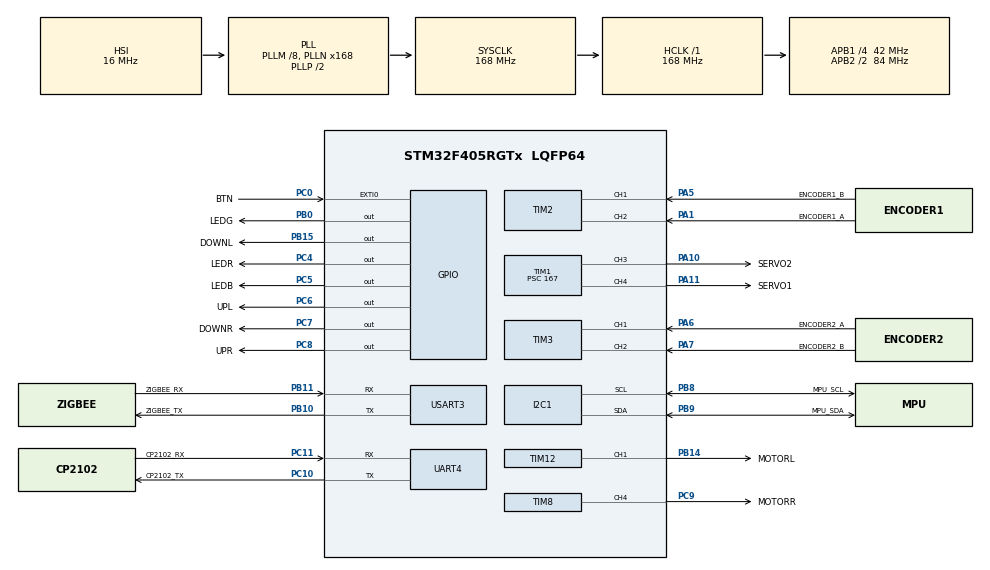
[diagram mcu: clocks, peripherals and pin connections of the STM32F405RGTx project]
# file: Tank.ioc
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Dma.Request0=UART4_RX
Dma.Request1=USART3_RX
Dma.UART4_RX.0.Direction=DMA_PERIPH_TO_MEMORY
Dma.UART4_RX.0.FIFOMode=DMA_FIFOMODE_DISABLE
Dma.UART4_RX.0.Instance=DMA1_Stream2
Dma.UART4_RX.0.MemDataAlignment=DMA_MDATAALIGN_BYTE
Dma.UART4_RX.0.MemInc=DMA_MINC_ENABLE
Dma.UART4_RX.0.Mode=DMA_NORMAL
Dma.UART4_RX.0.PeriphDataAlignment=DMA_PDATAALIGN_BYTE
Dma.UART4_RX.0.PeriphInc=DMA_PINC_DISABLE
Dma.UART4_RX.0.Priority=DMA_PRIORITY_LOW
Dma.USART3_RX.1.Direction=DMA_PERIPH_TO_MEMORY
Dma.USART3_RX.1.FIFOMode=DMA_FIFOMODE_DISABLE
Dma.USART3_RX.1.Instance=DMA1_Stream1
Dma.USART3_RX.1.MemDataAlignment=DMA_MDATAALIGN_BYTE
Dma.USART3_RX.1.MemInc=DMA_MINC_ENABLE
Dma.USART3_RX.1.Mode=DMA_NORMAL
Dma.USART3_RX.1.PeriphDataAlignment=DMA_PDATAALIGN_BYTE
Dma.USART3_RX.1.PeriphInc=DMA_PINC_DISABLE
Dma.USART3_RX.1.Priority=DMA_PRIORITY_LOW
Mcu.Family=STM32F4
Mcu.Name=STM32F405RGTx
Mcu.Package=LQFP64
NVIC.DMA1_Stream1_IRQn=true\:0\:0\:false\:false\:true\:false\:true
NVIC.DMA1_Stream2_IRQn=true\:0\:0\:false\:false\:true\:false\:true
NVIC.PriorityGroup=NVIC_PRIORITYGROUP_4
NVIC.UART4_IRQn=true\:0\:0\:false\:false\:true\:true\:true
NVIC.USART3_IRQn=true\:0\:0\:false\:false\:true\:true\:true
PA1.GPIO_Label=ENCODER1_A
PA1.GPIO_PuPd=GPIO_PULLUP
PA1.Signal=S_TIM2_CH2
PA10.GPIO_Label=SERVO2
PA10.Signal=S_TIM1_CH3
PA11.GPIO_Label=SERVO1
PA11.Signal=S_TIM1_CH4
PA13.Mode=Serial_Wire
PA13.Signal=SYS_JTMS-SWDIO
PA14.Mode=Serial_Wire
PA14.Signal=SYS_JTCK-SWCLK
PA5.GPIO_Label=ENCODER1_B
PA5.GPIO_PuPd=GPIO_PULLUP
PA5.Signal=S_TIM2_CH1_ETR
PA6.GPIO_Label=ENCODER2_A
PA6.GPIO_PuPd=GPIO_PULLUP
PA6.Signal=S_TIM3_CH1
PA7.GPIO_Label=ENCODER2_B
PA7.GPIO_PuPd=GPIO_PULLUP
PA7.Signal=S_TIM3_CH2
PB0.GPIO_Label=LEDG
PB0.Signal=GPIO_Output
PB10.GPIO_Label=ZIGBEE_TX
PB10.Mode=Asynchronous
PB10.Signal=USART3_TX
PB11.GPIO_Label=ZIGBEE_RX
PB11.Mode=Asynchronous
PB11.Signal=USART3_RX
PB14.GPIO_Label=MOTORL
PB14.Signal=S_TIM12_CH1
PB15.GPIO_Label=DOWNL
PB15.Signal=GPIO_Output
PB8.GPIO_Label=MPU_SCL
PB8.Mode=I2C
PB8.Signal=I2C1_SCL
PB9.GPIO_Label=MPU_SDA
PB9.Mode=I2C
PB9.Signal=I2C1_SDA
PC0.GPIO_Label=BTN
PC0.Signal=GPXTI0
PC10.GPIO_Label=CP2102_TX
PC10.Mode=Asynchronous
PC10.Signal=UART4_TX
PC11.GPIO_Label=CP2102_RX
PC11.Mode=Asynchronous
PC11.Signal=UART4_RX
PC4.GPIO_Label=LEDR
PC4.Signal=GPIO_Output
PC5.GPIO_Label=LEDB
PC5.Signal=GPIO_Output
PC6.GPIO_Label=UPL
PC6.Signal=GPIO_Output
PC7.GPIO_Label=DOWNR
PC7.Signal=GPIO_Output
PC8.GPIO_Label=UPR
PC8.Signal=GPIO_Output
PC9.GPIO_Label=MOTORR
PC9.Signal=S_TIM8_CH4
PH0-OSC_IN.Mode=HSE-External-Clock-Source
PH0-OSC_IN.Signal=RCC_OSC_IN
PH1-OSC_OUT.Mode=HSE-External-Clock-Source
PH1-OSC_OUT.Signal=RCC_OSC_OUT
ProjectManager.HeapSize=0x200
ProjectManager.StackSize=0x400
ProjectManager.TargetToolchain=STM32CubeIDE
RCC.48MHZClocksFreq_Value=84000000
RCC.AHBFreq_Value=168000000
RCC.APB1CLKDivider=RCC_HCLK_DIV4
RCC.APB1Freq_Value=42000000
RCC.APB1TimFreq_Value=84000000
RCC.APB2CLKDivider=RCC_HCLK_DIV2
RCC.APB2Freq_Value=84000000
RCC.APB2TimFreq_Value=168000000
RCC.CortexFreq_Value=168000000
RCC.HCLKFreq_Value=168000000
RCC.HSE_VALUE=25000000
RCC.HSI_VALUE=16000000
RCC.LSE_VALUE=32768
RCC.PLLM=8
RCC.PLLN=168
RCC.SYSCLKFreq_VALUE=168000000
RCC.SYSCLKSource=RCC_SYSCLKSOURCE_PLLCLK
RCC.VCOOutputFreq_Value=336000000
SH.S_TIM12_CH1.0=TIM12_CH1,PWM Generation1 CH1
SH.S_TIM1_CH3.0=TIM1_CH3,PWM Generation3 CH3
SH.S_TIM1_CH4.0=TIM1_CH4,PWM Generation4 CH4
SH.S_TIM2_CH1_ETR.0=TIM2_CH1,Encoder_Interface
SH.S_TIM2_CH2.0=TIM2_CH2,Encoder_Interface
SH.S_TIM3_CH1.0=TIM3_CH1,Encoder_Interface
SH.S_TIM3_CH2.0=TIM3_CH2,Encoder_Interface
SH.S_TIM8_CH4.0=TIM8_CH4,PWM Generation4 CH4
TIM1.Channel-PWM\ Generation3\ CH3=TIM_CHANNEL_3
TIM1.Channel-PWM\ Generation4\ CH4=TIM_CHANNEL_4
TIM1.Period=19999
TIM1.Prescaler=167
TIM12.Channel-PWM\ Generation1\ CH1=TIM_CHANNEL_1
TIM12.Period=3359
TIM8.Channel-PWM\ Generation4\ CH4=TIM_CHANNEL_4
TIM8.Period=3359
UART4.VirtualMode=Asynchronous
USART3.VirtualMode=VM_ASYNC
board=custom

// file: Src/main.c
/* USER CODE BEGIN Header */
/**
  ******************************************************************************
  * @file           : main.c
  * @brief          : Main program body
  ******************************************************************************
  * @attention
  *
  * <h2><center>&copy; Copyright (c) 2020 STMicroelectronics.
  * All rights reserved.</center></h2>
  *
  * This software component is licensed by ST under BSD 3-Clause license,
  * the "License"; You may not use this file except in compliance with the
  * License. You may obtain a copy of the License at:
  *                        opensource.org/licenses/BSD-3-Clause
  *
  ******************************************************************************
  */
/* USER CODE END Header */

#include "main.h"

I2C_HandleTypeDef hi2c1;

TIM_HandleTypeDef htim1;
TIM_HandleTypeDef htim2;
TIM_HandleTypeDef htim3;
TIM_HandleTypeDef htim8;
TIM_HandleTypeDef htim12;

UART_HandleTypeDef huart4;
UART_HandleTypeDef huart3;
DMA_HandleTypeDef hdma_uart4_rx;
DMA_HandleTypeDef hdma_usart3_rx;

/* USER CODE BEGIN PV */

extern char UARTgetchar[1],UARTbuffer[20];
extern uint8_t newblockdata;

/* USER CODE END PV */

void SystemClock_Config(void);
static void MX_GPIO_Init(void);
static void MX_DMA_Init(void);
static void MX_I2C1_Init(void);
static void MX_TIM1_Init(void);
static void MX_TIM2_Init(void);
static void MX_TIM3_Init(void);
static void MX_TIM8_Init(void);
static void MX_UART4_Init(void);
static void MX_USART3_UART_Init(void);
static void MX_TIM12_Init(void);

/* USER CODE BEGIN 0 */
void HAL_UART_RxCpltCallback(UART_HandleTypeDef *huart)
{
	switch (huart->Instance) {
		case UART4:

			break;
		default:
			break;
	}
}
/* USER CODE END 0 */

int main(void)
{

  /* MCU Configuration--------------------------------------------------------*/

  /* Reset of all peripherals, Initializes the Flash interface and the Systick. */
  HAL_Init();

  /* USER CODE BEGIN Init */
  HAL_UART_Receive_IT(&huart4, UARTgetchar, 1);
  /* USER CODE END Init */

  /* Configure the system clock */
  SystemClock_Config();

  /* Initialize all configured peripherals */
  MX_GPIO_Init();
  MX_DMA_Init();
  MX_I2C1_Init();
  MX_TIM1_Init();
  MX_TIM2_Init();
  MX_TIM3_Init();
  MX_TIM8_Init();
  MX_UART4_Init();
  MX_USART3_UART_Init();
  MX_TIM12_Init();

  /* Infinite loop */
  while (1)
  {

  }
}

void SystemClock_Config(void)
{
  RCC_OscInitTypeDef RCC_OscInitStruct = {0};
  RCC_ClkInitTypeDef RCC_ClkInitStruct = {0};

  /** Configure the main internal regulator output voltage
  */
  __HAL_RCC_PWR_CLK_ENABLE();
  __HAL_PWR_VOLTAGESCALING_CONFIG(PWR_REGULATOR_VOLTAGE_SCALE1);
  /** Initializes the CPU, AHB and APB busses clocks
  */
  RCC_OscInitStruct.OscillatorType = RCC_OSCILLATORTYPE_HSI;
  RCC_OscInitStruct.HSIState = RCC_HSI_ON;
  RCC_OscInitStruct.HSICalibrationValue = RCC_HSICALIBRATION_DEFAULT;
  RCC_OscInitStruct.PLL.PLLState = RCC_PLL_ON;
  RCC_OscInitStruct.PLL.PLLSource = RCC_PLLSOURCE_HSI;
  RCC_OscInitStruct.PLL.PLLM = 8;
  RCC_OscInitStruct.PLL.PLLN = 168;
  RCC_OscInitStruct.PLL.PLLP = RCC_PLLP_DIV2;
  RCC_OscInitStruct.PLL.PLLQ = 4;
  if (HAL_RCC_OscConfig(&RCC_OscInitStruct) != HAL_OK)
  {
    Error_Handler();
  }
  /** Initializes the CPU, AHB and APB busses clocks
  */
  RCC_ClkInitStruct.ClockType = RCC_CLOCKTYPE_HCLK|RCC_CLOCKTYPE_SYSCLK
                              |RCC_CLOCKTYPE_PCLK1|RCC_CLOCKTYPE_PCLK2;
  RCC_ClkInitStruct.SYSCLKSource = RCC_SYSCLKSOURCE_PLLCLK;
  RCC_ClkInitStruct.AHBCLKDivider = RCC_SYSCLK_DIV1;
  RCC_ClkInitStruct.APB1CLKDivider = RCC_HCLK_DIV4;
  RCC_ClkInitStruct.APB2CLKDivider = RCC_HCLK_DIV2;

  if (HAL_RCC_ClockConfig(&RCC_ClkInitStruct, FLASH_LATENCY_5) != HAL_OK)
  {
    Error_Handler();
  }
}

static void MX_I2C1_Init(void)
{

  hi2c1.Instance = I2C1;
  hi2c1.Init.ClockSpeed = 100000;
  hi2c1.Init.DutyCycle = I2C_DUTYCYCLE_2;
  hi2c1.Init.OwnAddress1 = 0;
  hi2c1.Init.AddressingMode = I2C_ADDRESSINGMODE_7BIT;
  hi2c1.Init.DualAddressMode = I2C_DUALADDRESS_DISABLE;
  hi2c1.Init.OwnAddress2 = 0;
  hi2c1.Init.GeneralCallMode = I2C_GENERALCALL_DISABLE;
  hi2c1.Init.NoStretchMode = I2C_NOSTRETCH_DISABLE;
  if (HAL_I2C_Init(&hi2c1) != HAL_OK)
  {
    Error_Handler();
  }

}

static void MX_TIM1_Init(void)
{

  TIM_MasterConfigTypeDef sMasterConfig = {0};
  TIM_OC_InitTypeDef sConfigOC = {0};
  TIM_BreakDeadTimeConfigTypeDef sBreakDeadTimeConfig = {0};

  htim1.Instance = TIM1;
  htim1.Init.Prescaler = 167;
  htim1.Init.CounterMode = TIM_COUNTERMODE_UP;
  htim1.Init.Period = 19999;
  htim1.Init.ClockDivision = TIM_CLOCKDIVISION_DIV1;
  htim1.Init.RepetitionCounter = 0;
  htim1.Init.AutoReloadPreload = TIM_AUTORELOAD_PRELOAD_DISABLE;
  if (HAL_TIM_PWM_Init(&htim1) != HAL_OK)
  {
    Error_Handler();
  }
  sMasterConfig.MasterOutputTrigger = TIM_TRGO_RESET;
  sMasterConfig.MasterSlaveMode = TIM_MASTERSLAVEMODE_DISABLE;
  if (HAL_TIMEx_MasterConfigSynchronization(&htim1, &sMasterConfig) != HAL_OK)
  {
    Error_Handler();
  }
  sConfigOC.OCMode = TIM_OCMODE_PWM1;
  sConfigOC.Pulse = 0;
  sConfigOC.OCPolarity = TIM_OCPOLARITY_HIGH;
  sConfigOC.OCNPolarity = TIM_OCNPOLARITY_HIGH;
  sConfigOC.OCFastMode = TIM_OCFAST_DISABLE;
  sConfigOC.OCIdleState = TIM_OCIDLESTATE_RESET;
  sConfigOC.OCNIdleState = TIM_OCNIDLESTATE_RESET;
  if (HAL_TIM_PWM_ConfigChannel(&htim1, &sConfigOC, TIM_CHANNEL_3) != HAL_OK)
  {
    Error_Handler();
  }
  if (HAL_TIM_PWM_ConfigChannel(&htim1, &sConfigOC, TIM_CHANNEL_4) != HAL_OK)
  {
    Error_Handler();
  }
  sBreakDeadTimeConfig.OffStateRunMode = TIM_OSSR_DISABLE;
  sBreakDeadTimeConfig.OffStateIDLEMode = TIM_OSSI_DISABLE;
  sBreakDeadTimeConfig.LockLevel = TIM_LOCKLEVEL_OFF;
  sBreakDeadTimeConfig.DeadTime = 0;
  sBreakDeadTimeConfig.BreakState = TIM_BREAK_DISABLE;
  sBreakDeadTimeConfig.BreakPolarity = TIM_BREAKPOLARITY_HIGH;
  sBreakDeadTimeConfig.AutomaticOutput = TIM_AUTOMATICOUTPUT_DISABLE;
  if (HAL_TIMEx_ConfigBreakDeadTime(&htim1, &sBreakDeadTimeConfig) != HAL_OK)
  {
    Error_Handler();
  }
  HAL_TIM_MspPostInit(&htim1);

}

static void MX_TIM2_Init(void)
{

  TIM_Encoder_InitTypeDef sConfig = {0};
  TIM_MasterConfigTypeDef sMasterConfig = {0};

  htim2.Instance = TIM2;
  htim2.Init.Prescaler = 0;
  htim2.Init.CounterMode = TIM_COUNTERMODE_UP;
  htim2.Init.Period = 0;
  htim2.Init.ClockDivision = TIM_CLOCKDIVISION_DIV1;
  htim2.Init.AutoReloadPreload = TIM_AUTORELOAD_PRELOAD_DISABLE;
  sConfig.EncoderMode = TIM_ENCODERMODE_TI1;
  sConfig.IC1Polarity = TIM_ICPOLARITY_RISING;
  sConfig.IC1Selection = TIM_ICSELECTION_DIRECTTI;
  sConfig.IC1Prescaler = TIM_ICPSC_DIV1;
  sConfig.IC1Filter = 0;
  sConfig.IC2Polarity = TIM_ICPOLARITY_RISING;
  sConfig.IC2Selection = TIM_ICSELECTION_DIRECTTI;
  sConfig.IC2Prescaler = TIM_ICPSC_DIV1;
  sConfig.IC2Filter = 0;
  if (HAL_TIM_Encoder_Init(&htim2, &sConfig) != HAL_OK)
  {
    Error_Handler();
  }
  sMasterConfig.MasterOutputTrigger = TIM_TRGO_RESET;
  sMasterConfig.MasterSlaveMode = TIM_MASTERSLAVEMODE_DISABLE;
  if (HAL_TIMEx_MasterConfigSynchronization(&htim2, &sMasterConfig) != HAL_OK)
  {
    Error_Handler();
  }

}

static void MX_TIM3_Init(void)
{

  TIM_Encoder_InitTypeDef sConfig = {0};
  TIM_MasterConfigTypeDef sMasterConfig = {0};

  htim3.Instance = TIM3;
  htim3.Init.Prescaler = 0;
  htim3.Init.CounterMode = TIM_COUNTERMODE_UP;
  htim3.Init.Period = 0;
  htim3.Init.ClockDivision = TIM_CLOCKDIVISION_DIV1;
  htim3.Init.AutoReloadPreload = TIM_AUTORELOAD_PRELOAD_DISABLE;
  sConfig.EncoderMode = TIM_ENCODERMODE_TI1;
  sConfig.IC1Polarity = TIM_ICPOLARITY_RISING;
  sConfig.IC1Selection = TIM_ICSELECTION_DIRECTTI;
  sConfig.IC1Prescaler = TIM_ICPSC_DIV1;
  sConfig.IC1Filter = 0;
  sConfig.IC2Polarity = TIM_ICPOLARITY_RISING;
  sConfig.IC2Selection = TIM_ICSELECTION_DIRECTTI;
  sConfig.IC2Prescaler = TIM_ICPSC_DIV1;
  sConfig.IC2Filter = 0;
  if (HAL_TIM_Encoder_Init(&htim3, &sConfig) != HAL_OK)
  {
    Error_Handler();
  }
  sMasterConfig.MasterOutputTrigger = TIM_TRGO_RESET;
  sMasterConfig.MasterSlaveMode = TIM_MASTERSLAVEMODE_DISABLE;
  if (HAL_TIMEx_MasterConfigSynchronization(&htim3, &sMasterConfig) != HAL_OK)
  {
    Error_Handler();
  }

}

static void MX_TIM8_Init(void)
{

  TIM_MasterConfigTypeDef sMasterConfig = {0};
  TIM_OC_InitTypeDef sConfigOC = {0};
  TIM_BreakDeadTimeConfigTypeDef sBreakDeadTimeConfig = {0};

  htim8.Instance = TIM8;
  htim8.Init.Prescaler = 0;
  htim8.Init.CounterMode = TIM_COUNTERMODE_UP;
  htim8.Init.Period = 3359;
  htim8.Init.ClockDivision = TIM_CLOCKDIVISION_DIV1;
  htim8.Init.RepetitionCounter = 0;
  htim8.Init.AutoReloadPreload = TIM_AUTORELOAD_PRELOAD_DISABLE;
  if (HAL_TIM_PWM_Init(&htim8) != HAL_OK)
  {
    Error_Handler();
  }
  sMasterConfig.MasterOutputTrigger = TIM_TRGO_RESET;
  sMasterConfig.MasterSlaveMode = TIM_MASTERSLAVEMODE_DISABLE;
  if (HAL_TIMEx_MasterConfigSynchronization(&htim8, &sMasterConfig) != HAL_OK)
  {
    Error_Handler();
  }
  sConfigOC.OCMode = TIM_OCMODE_PWM1;
  sConfigOC.Pulse = 0;
  sConfigOC.OCPolarity = TIM_OCPOLARITY_HIGH;
  sConfigOC.OCFastMode = TIM_OCFAST_DISABLE;
  sConfigOC.OCIdleState = TIM_OCIDLESTATE_RESET;
  sConfigOC.OCNIdleState = TIM_OCNIDLESTATE_RESET;
  if (HAL_TIM_PWM_ConfigChannel(&htim8, &sConfigOC, TIM_CHANNEL_4) != HAL_OK)
  {
    Error_Handler();
  }
  sBreakDeadTimeConfig.OffStateRunMode = TIM_OSSR_DISABLE;
  sBreakDeadTimeConfig.OffStateIDLEMode = TIM_OSSI_DISABLE;
  sBreakDeadTimeConfig.LockLevel = TIM_LOCKLEVEL_OFF;
  sBreakDeadTimeConfig.DeadTime = 0;
  sBreakDeadTimeConfig.BreakState = TIM_BREAK_DISABLE;
  sBreakDeadTimeConfig.BreakPolarity = TIM_BREAKPOLARITY_HIGH;
  sBreakDeadTimeConfig.AutomaticOutput = TIM_AUTOMATICOUTPUT_DISABLE;
  if (HAL_TIMEx_ConfigBreakDeadTime(&htim8, &sBreakDeadTimeConfig) != HAL_OK)
  {
    Error_Handler();
  }
  HAL_TIM_MspPostInit(&htim8);

}

static void MX_TIM12_Init(void)
{

  TIM_OC_InitTypeDef sConfigOC = {0};

  htim12.Instance = TIM12;
  htim12.Init.Prescaler = 0;
  htim12.Init.CounterMode = TIM_COUNTERMODE_UP;
  htim12.Init.Period = 3359;
  htim12.Init.ClockDivision = TIM_CLOCKDIVISION_DIV1;
  htim12.Init.AutoReloadPreload = TIM_AUTORELOAD_PRELOAD_DISABLE;
  if (HAL_TIM_PWM_Init(&htim12) != HAL_OK)
  {
    Error_Handler();
  }
  sConfigOC.OCMode = TIM_OCMODE_PWM1;
  sConfigOC.Pulse = 0;
  sConfigOC.OCPolarity = TIM_OCPOLARITY_HIGH;
  sConfigOC.OCFastMode = TIM_OCFAST_DISABLE;
  if (HAL_TIM_PWM_ConfigChannel(&htim12, &sConfigOC, TIM_CHANNEL_1) != HAL_OK)
  {
    Error_Handler();
  }
  HAL_TIM_MspPostInit(&htim12);

}

static void MX_UART4_Init(void)
{

  huart4.Instance = UART4;
  huart4.Init.BaudRate = 115200;
  huart4.Init.WordLength = UART_WORDLENGTH_8B;
  huart4.Init.StopBits = UART_STOPBITS_1;
  huart4.Init.Parity = UART_PARITY_NONE;
  huart4.Init.Mode = UART_MODE_TX_RX;
  huart4.Init.HwFlowCtl = UART_HWCONTROL_NONE;
  huart4.Init.OverSampling = UART_OVERSAMPLING_16;
  if (HAL_UART_Init(&huart4) != HAL_OK)
  {
    Error_Handler();
  }

}

static void MX_USART3_UART_Init(void)
{

  huart3.Instance = USART3;
  huart3.Init.BaudRate = 115200;
  huart3.Init.WordLength = UART_WORDLENGTH_8B;
  huart3.Init.StopBits = UART_STOPBITS_1;
  huart3.Init.Parity = UART_PARITY_NONE;
  huart3.Init.Mode = UART_MODE_TX_RX;
  huart3.Init.HwFlowCtl = UART_HWCONTROL_NONE;
  huart3.Init.OverSampling = UART_OVERSAMPLING_16;
  if (HAL_UART_Init(&huart3) != HAL_OK)
  {
    Error_Handler();
  }

}

static void MX_DMA_Init(void)
{

  /* DMA controller clock enable */
  __HAL_RCC_DMA1_CLK_ENABLE();

  /* DMA interrupt init */
  /* DMA1_Stream1_IRQn interrupt configuration */
  HAL_NVIC_SetPriority(DMA1_Stream1_IRQn, 0, 0);
  HAL_NVIC_EnableIRQ(DMA1_Stream1_IRQn);
  /* DMA1_Stream2_IRQn interrupt configuration */
  HAL_NVIC_SetPriority(DMA1_Stream2_IRQn, 0, 0);
  HAL_NVIC_EnableIRQ(DMA1_Stream2_IRQn);

}

static void MX_GPIO_Init(void)
{
  GPIO_InitTypeDef GPIO_InitStruct = {0};

  /* GPIO Ports Clock Enable */
  __HAL_RCC_GPIOH_CLK_ENABLE();
  __HAL_RCC_GPIOC_CLK_ENABLE();
  __HAL_RCC_GPIOA_CLK_ENABLE();
  __HAL_RCC_GPIOB_CLK_ENABLE();

  /*Configure GPIO pin Output Level */
  HAL_GPIO_WritePin(GPIOC, LEDR_Pin|LEDB_Pin|UPL_Pin|DOWNR_Pin
                          |UPR_Pin, GPIO_PIN_RESET);

  /*Configure GPIO pin Output Level */
  HAL_GPIO_WritePin(GPIOB, LEDG_Pin|DOWNL_Pin, GPIO_PIN_RESET);

  /*Configure GPIO pin : BTN_Pin */
  GPIO_InitStruct.Pin = BTN_Pin;
  GPIO_InitStruct.Mode = GPIO_MODE_IT_RISING;
  GPIO_InitStruct.Pull = GPIO_NOPULL;
  HAL_GPIO_Init(BTN_GPIO_Port, &GPIO_InitStruct);

  /*Configure GPIO pins : LEDR_Pin LEDB_Pin UPL_Pin DOWNR_Pin
                           UPR_Pin */
  GPIO_InitStruct.Pin = LEDR_Pin|LEDB_Pin|UPL_Pin|DOWNR_Pin
                          |UPR_Pin;
  GPIO_InitStruct.Mode = GPIO_MODE_OUTPUT_PP;
  GPIO_InitStruct.Pull = GPIO_NOPULL;
  GPIO_InitStruct.Speed = GPIO_SPEED_FREQ_LOW;
  HAL_GPIO_Init(GPIOC, &GPIO_InitStruct);

  /*Configure GPIO pins : LEDG_Pin DOWNL_Pin */
  GPIO_InitStruct.Pin = LEDG_Pin|DOWNL_Pin;
  GPIO_InitStruct.Mode = GPIO_MODE_OUTPUT_PP;
  GPIO_InitStruct.Pull = GPIO_NOPULL;
  GPIO_InitStruct.Speed = GPIO_SPEED_FREQ_LOW;
  HAL_GPIO_Init(GPIOB, &GPIO_InitStruct);

}

void Error_Handler(void)
{
}

/************************ (C) COPYRIGHT STMicroelectronics *****END OF FILE****/
